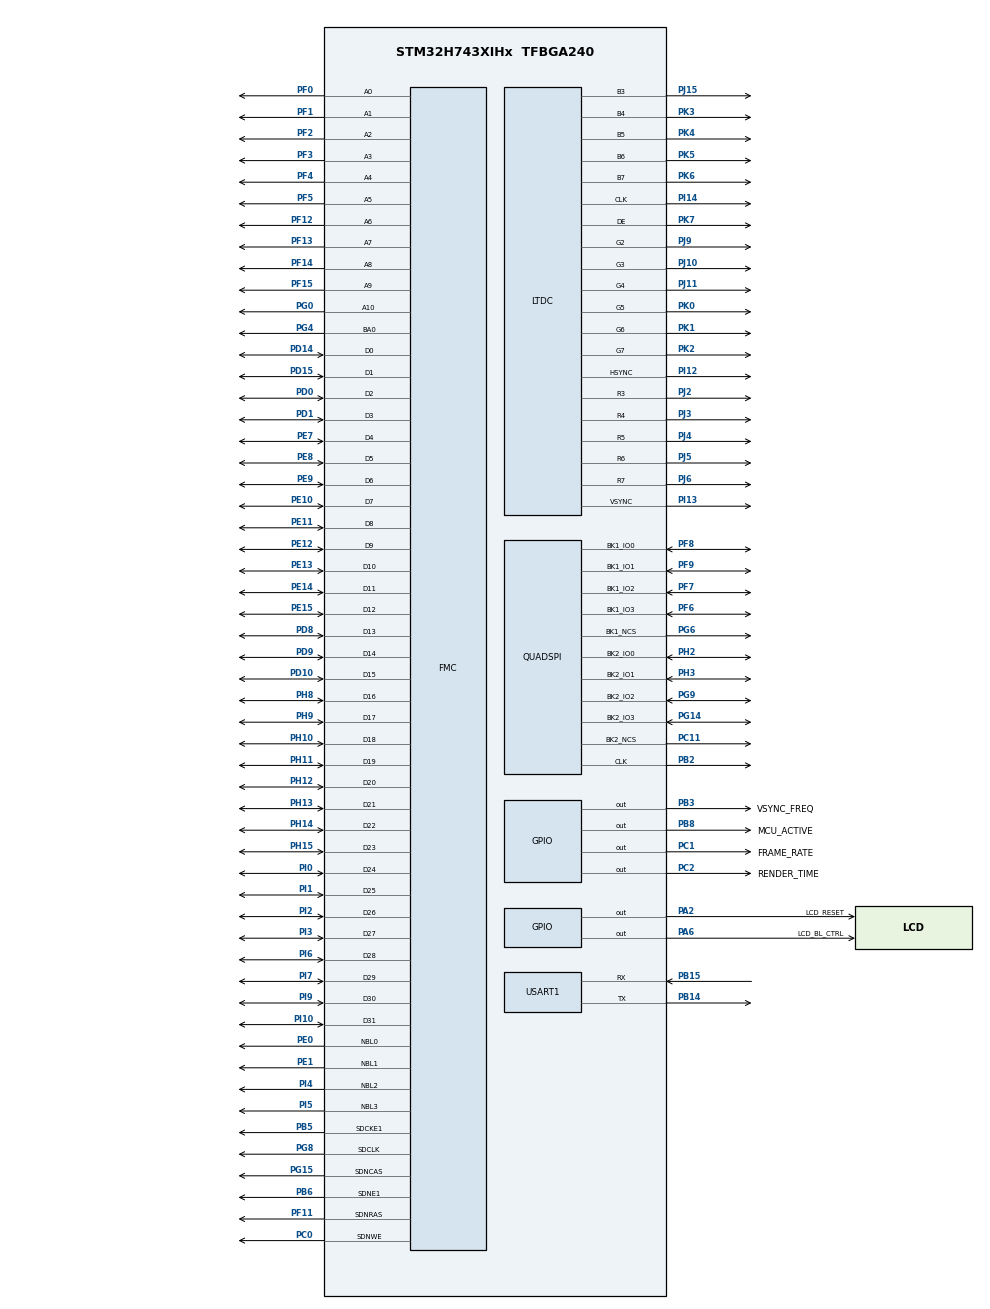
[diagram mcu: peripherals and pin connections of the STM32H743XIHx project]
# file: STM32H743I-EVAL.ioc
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CORTEX_M7.AccessPermission-Cortex_Memory_Protection_Unit_Region0_Settings=MPU_REGION_FULL_ACCESS
CORTEX_M7.AccessPermission-Cortex_Memory_Protection_Unit_Region2_Settings=MPU_REGION_FULL_ACCESS
CORTEX_M7.AccessPermission-Cortex_Memory_Protection_Unit_Region4_Settings=MPU_REGION_FULL_ACCESS
CORTEX_M7.BaseAddress-Cortex_Memory_Protection_Unit_Region0_Settings=0x24000000
CORTEX_M7.BaseAddress-Cortex_Memory_Protection_Unit_Region1_Settings=0xD0000000
CORTEX_M7.BaseAddress-Cortex_Memory_Protection_Unit_Region2_Settings=0xD0000000
CORTEX_M7.BaseAddress-Cortex_Memory_Protection_Unit_Region3_Settings=0x90000000
CORTEX_M7.BaseAddress-Cortex_Memory_Protection_Unit_Region4_Settings=0x90000000
CORTEX_M7.CPU_DCache=Enabled
CORTEX_M7.CPU_ICache=Enabled
CORTEX_M7.DisableExec-Cortex_Memory_Protection_Unit_Region0_Settings=MPU_INSTRUCTION_ACCESS_DISABLE
CORTEX_M7.DisableExec-Cortex_Memory_Protection_Unit_Region1_Settings=MPU_INSTRUCTION_ACCESS_DISABLE
CORTEX_M7.DisableExec-Cortex_Memory_Protection_Unit_Region2_Settings=MPU_INSTRUCTION_ACCESS_DISABLE
CORTEX_M7.DisableExec-Cortex_Memory_Protection_Unit_Region3_Settings=MPU_INSTRUCTION_ACCESS_DISABLE
CORTEX_M7.DisableExec-Cortex_Memory_Protection_Unit_Region4_Settings=MPU_INSTRUCTION_ACCESS_DISABLE
CORTEX_M7.Enable-Cortex_Memory_Protection_Unit_Region0_Settings=MPU_REGION_ENABLE
CORTEX_M7.Enable-Cortex_Memory_Protection_Unit_Region1_Settings=MPU_REGION_ENABLE
CORTEX_M7.Enable-Cortex_Memory_Protection_Unit_Region2_Settings=MPU_REGION_ENABLE
CORTEX_M7.Enable-Cortex_Memory_Protection_Unit_Region3_Settings=MPU_REGION_ENABLE
CORTEX_M7.Enable-Cortex_Memory_Protection_Unit_Region4_Settings=MPU_REGION_ENABLE
CORTEX_M7.IsBufferable-Cortex_Memory_Protection_Unit_Region0_Settings=MPU_ACCESS_BUFFERABLE
CORTEX_M7.IsBufferable-Cortex_Memory_Protection_Unit_Region2_Settings=MPU_ACCESS_BUFFERABLE
CORTEX_M7.IsBufferable-Cortex_Memory_Protection_Unit_Region4_Settings=MPU_ACCESS_NOT_BUFFERABLE
CORTEX_M7.IsCacheable-Cortex_Memory_Protection_Unit_Region0_Settings=MPU_ACCESS_CACHEABLE
CORTEX_M7.IsCacheable-Cortex_Memory_Protection_Unit_Region2_Settings=MPU_ACCESS_CACHEABLE
CORTEX_M7.IsCacheable-Cortex_Memory_Protection_Unit_Region4_Settings=MPU_ACCESS_CACHEABLE
CORTEX_M7.MPU_Control=MPU_PRIVILEGED_DEFAULT
CORTEX_M7.Size-Cortex_Memory_Protection_Unit_Region0_Settings=MPU_REGION_SIZE_512KB
CORTEX_M7.Size-Cortex_Memory_Protection_Unit_Region1_Settings=MPU_REGION_SIZE_512MB
CORTEX_M7.Size-Cortex_Memory_Protection_Unit_Region2_Settings=MPU_REGION_SIZE_32MB
CORTEX_M7.Size-Cortex_Memory_Protection_Unit_Region3_Settings=MPU_REGION_SIZE_512MB
CORTEX_M7.Size-Cortex_Memory_Protection_Unit_Region4_Settings=MPU_REGION_SIZE_128MB
DMA2D.ColorMode=DMA2D_OUTPUT_RGB565
DMA2D.Mode=DMA2D_R2M
FREERTOS.Tasks01=defaultTask,24,128,StartDefaultTask,Default,NULL,Dynamic,NULL,NULL;TouchGFXTask,24,4096,TouchGFX_Task,As external,NULL,Dynamic,NULL,NULL
FREERTOS.configTOTAL_HEAP_SIZE=32768
FREERTOS.configUSE_APPLICATION_TASK_TAG=1
FREERTOS.configUSE_IDLE_HOOK=1
FREERTOS.configUSE_NEWLIB_REENTRANT=1
LTDC.Alpha0_L0=0
LTDC.Alpha_L0=255
LTDC.BlendingFactor1_L0=LTDC_BLENDING_FACTOR1_CA
LTDC.BlendingFactor2_L0=LTDC_BLENDING_FACTOR2_CA
LTDC.FBStartAdress_L0=0xD0000000
LTDC.HBP=114
LTDC.HFP=16
LTDC.HSync=30
LTDC.ImageHeight_L0=480
LTDC.ImageWidth_L0=640
LTDC.Layers=0
LTDC.PixelFormat_L0=LTDC_PIXEL_FORMAT_RGB565
LTDC.VBP=32
LTDC.VFP=10
LTDC.VSync=3
LTDC.WindowX1_L0=640
LTDC.WindowY1_L0=480
Mcu.Family=STM32H7
Mcu.Name=STM32H743XIHx
Mcu.Package=TFBGA240
NVIC.DMA2D_IRQn=true\:5\:0\:false\:false\:true\:true\:true\:true\:true
NVIC.LTDC_IRQn=true\:15\:0\:true\:false\:true\:false\:true\:true\:true
NVIC.PriorityGroup=NVIC_PRIORITYGROUP_4
NVIC.TIM6_DAC_IRQn=true\:0\:0\:false\:false\:true\:false\:false\:true\:true
NVIC.TimeBase=TIM6_DAC_IRQn
NVIC.TimeBaseIP=TIM6
NVIC.USART1_IRQn=true\:5\:0\:false\:false\:true\:true\:true\:true\:true
PA2.GPIO_Label=LCD_RESET
PA2.Signal=GPIO_Output
PA6.GPIO_Label=LCD_BL_CTRL
PA6.GPIO_Speed=GPIO_SPEED_FREQ_HIGH
PA6.PinState=GPIO_PIN_SET
PA6.Signal=GPIO_Output
PB14.Mode=Asynchronous
PB14.Signal=USART1_TX
PB15.Mode=Asynchronous
PB15.Signal=USART1_RX
PB2.GPIO_Speed=GPIO_SPEED_FREQ_VERY_HIGH
PB2.Mode=Dual_Bank
PB2.Signal=QUADSPI_CLK
PB3\ (JTDO/TRACESWO).GPIO_Label=VSYNC_FREQ
PB3\ (JTDO/TRACESWO).GPIO_Speed=GPIO_SPEED_FREQ_VERY_HIGH
PB3\ (JTDO/TRACESWO).Signal=GPIO_Output
PB5.Mode=SdramChipSelect2_1
PB5.Signal=FMC_SDCKE1
PB6.Mode=SdramChipSelect2_1
PB6.Signal=FMC_SDNE1
PB8.GPIO_Label=MCU_ACTIVE
PB8.GPIO_Speed=GPIO_SPEED_FREQ_VERY_HIGH
PB8.Signal=GPIO_Output
PC0.Signal=FMC_SDNWE
PC1.GPIO_Label=FRAME_RATE
PC1.GPIO_Speed=GPIO_SPEED_FREQ_VERY_HIGH
PC1.Signal=GPIO_Output
PC11.GPIO_PuPd=GPIO_PULLUP
PC11.GPIO_Speed=GPIO_SPEED_FREQ_VERY_HIGH
PC11.Mode=Enable Chip Select for each bank
PC11.Signal=QUADSPI_BK2_NCS
PC2.GPIO_Label=RENDER_TIME
PC2.GPIO_Speed=GPIO_SPEED_FREQ_VERY_HIGH
PC2.Signal=GPIO_Output
PD0.Signal=FMC_D2_DA2
PD1.Signal=FMC_D3_DA3
PD10.Signal=FMC_D15_DA15
PD14.Signal=FMC_D0_DA0
PD15.Signal=FMC_D1_DA1
PD8.Signal=FMC_D13_DA13
PD9.Signal=FMC_D14_DA14
PE0.Signal=FMC_NBL0
PE1.Signal=FMC_NBL1
PE10.Signal=FMC_D7_DA7
PE11.Signal=FMC_D8_DA8
PE12.Signal=FMC_D9_DA9
PE13.Signal=FMC_D10_DA10
PE14.Signal=FMC_D11_DA11
PE15.Signal=FMC_D12_DA12
PE7.Signal=FMC_D4_DA4
PE8.Signal=FMC_D5_DA5
PE9.Signal=FMC_D6_DA6
PF0.Signal=FMC_A0
PF1.Signal=FMC_A1
PF11.Signal=FMC_SDNRAS
PF12.Signal=FMC_A6
PF13.Signal=FMC_A7
PF14.Signal=FMC_A8
PF15.Signal=FMC_A9
PF2.Signal=FMC_A2
PF3.Signal=FMC_A3
PF4.Signal=FMC_A4
PF5.Signal=FMC_A5
PF6.GPIO_Speed=GPIO_SPEED_FREQ_VERY_HIGH
PF6.Mode=Dual_Bank
PF6.Signal=QUADSPI_BK1_IO3
PF7.GPIO_Speed=GPIO_SPEED_FREQ_VERY_HIGH
PF7.Mode=Dual_Bank
PF7.Signal=QUADSPI_BK1_IO2
PF8.GPIO_Speed=GPIO_SPEED_FREQ_VERY_HIGH
PF8.Mode=Dual_Bank
PF8.Signal=QUADSPI_BK1_IO0
PF9.GPIO_Speed=GPIO_SPEED_FREQ_VERY_HIGH
PF9.Mode=Dual_Bank
PF9.Signal=QUADSPI_BK1_IO1
PG0.Signal=FMC_A10
PG14.GPIO_Speed=GPIO_SPEED_FREQ_VERY_HIGH
PG14.Mode=Dual_Bank
PG14.Signal=QUADSPI_BK2_IO3
PG15.Signal=FMC_SDNCAS
PG4.Signal=FMC_A14_BA0
PG6.GPIO_PuPd=GPIO_PULLUP
PG6.GPIO_Speed=GPIO_SPEED_FREQ_VERY_HIGH
PG6.Mode=Enable Chip Select for each bank
PG6.Signal=QUADSPI_BK1_NCS
PG8.Signal=FMC_SDCLK
PG9.GPIO_Speed=GPIO_SPEED_FREQ_VERY_HIGH
PG9.Mode=Dual_Bank
PG9.Signal=QUADSPI_BK2_IO2
PH0-OSC_IN\ (PH0).Mode=HSE-External-Oscillator
PH0-OSC_IN\ (PH0).Signal=RCC_OSC_IN
PH1-OSC_OUT\ (PH1).Mode=HSE-External-Oscillator
PH1-OSC_OUT\ (PH1).Signal=RCC_OSC_OUT
PH10.Signal=FMC_D18
PH11.Signal=FMC_D19
PH12.Signal=FMC_D20
PH13.Signal=FMC_D21
PH14.Signal=FMC_D22
PH15.Signal=FMC_D23
PH2.GPIO_Speed=GPIO_SPEED_FREQ_VERY_HIGH
PH2.Mode=Dual_Bank
PH2.Signal=QUADSPI_BK2_IO0
PH3.GPIO_Speed=GPIO_SPEED_FREQ_VERY_HIGH
PH3.Mode=Dual_Bank
PH3.Signal=QUADSPI_BK2_IO1
PH8.Signal=FMC_D16
PH9.Signal=FMC_D17
PI0.Signal=FMC_D24
PI1.Signal=FMC_D25
PI10.Signal=FMC_D31
PI12.GPIO_Speed=GPIO_SPEED_FREQ_VERY_HIGH
PI12.Mode=RGB565
PI12.Signal=LTDC_HSYNC
PI13.GPIO_Speed=GPIO_SPEED_FREQ_VERY_HIGH
PI13.Mode=RGB565
PI13.Signal=LTDC_VSYNC
PI14.GPIO_Speed=GPIO_SPEED_FREQ_VERY_HIGH
PI14.Mode=RGB565
PI14.Signal=LTDC_CLK
PI15.GPIO_Speed=GPIO_SPEED_FREQ_VERY_HIGH
PI15.Signal=LTDC_R0
PI2.Signal=FMC_D26
PI3.Signal=FMC_D27
PI4.Signal=FMC_NBL2
PI5.Signal=FMC_NBL3
PI6.Signal=FMC_D28
PI7.Signal=FMC_D29
PI9.Signal=FMC_D30
PJ0.GPIO_Speed=GPIO_SPEED_FREQ_VERY_HIGH
PJ0.Signal=LTDC_R1
PJ10.GPIO_Speed=GPIO_SPEED_FREQ_VERY_HIGH
PJ10.Mode=RGB565
PJ10.Signal=LTDC_G3
PJ11.GPIO_Speed=GPIO_SPEED_FREQ_VERY_HIGH
PJ11.Mode=RGB565
PJ11.Signal=LTDC_G4
PJ15.GPIO_Speed=GPIO_SPEED_FREQ_VERY_HIGH
PJ15.Mode=RGB565
PJ15.Signal=LTDC_B3
PJ2.GPIO_Speed=GPIO_SPEED_FREQ_VERY_HIGH
PJ2.Mode=RGB565
PJ2.Signal=LTDC_R3
PJ3.GPIO_Speed=GPIO_SPEED_FREQ_VERY_HIGH
PJ3.Mode=RGB565
PJ3.Signal=LTDC_R4
PJ4.GPIO_Speed=GPIO_SPEED_FREQ_VERY_HIGH
PJ4.Mode=RGB565
PJ4.Signal=LTDC_R5
PJ5.GPIO_Speed=GPIO_SPEED_FREQ_VERY_HIGH
PJ5.Mode=RGB565
PJ5.Signal=LTDC_R6
PJ6.GPIO_Speed=GPIO_SPEED_FREQ_VERY_HIGH
PJ6.Mode=RGB565
PJ6.Signal=LTDC_R7
PJ9.GPIO_Speed=GPIO_SPEED_FREQ_VERY_HIGH
PJ9.Mode=RGB565
PJ9.Signal=LTDC_G2
PK0.GPIO_Speed=GPIO_SPEED_FREQ_VERY_HIGH
PK0.Mode=RGB565
PK0.Signal=LTDC_G5
PK1.GPIO_Speed=GPIO_SPEED_FREQ_VERY_HIGH
PK1.Mode=RGB565
PK1.Signal=LTDC_G6
PK2.GPIO_Speed=GPIO_SPEED_FREQ_VERY_HIGH
PK2.Mode=RGB565
PK2.Signal=LTDC_G7
PK3.GPIO_Speed=GPIO_SPEED_FREQ_VERY_HIGH
PK3.Mode=RGB565
PK3.Signal=LTDC_B4
PK4.GPIO_Speed=GPIO_SPEED_FREQ_VERY_HIGH
PK4.Mode=RGB565
PK4.Signal=LTDC_B5
PK5.GPIO_Speed=GPIO_SPEED_FREQ_VERY_HIGH
PK5.Mode=RGB565
PK5.Signal=LTDC_B6
PK6.GPIO_Speed=GPIO_SPEED_FREQ_VERY_HIGH
PK6.Mode=RGB565
PK6.Signal=LTDC_B7
PK7.GPIO_Speed=GPIO_SPEED_FREQ_VERY_HIGH
PK7.Mode=RGB565
PK7.Signal=LTDC_DE
ProjectManager.HeapSize=0x1000
ProjectManager.StackSize=0x1000
ProjectManager.TargetToolchain=STM32CubeIDE
QUADSPI.ChipSelectHighTime=QSPI_CS_HIGH_TIME_4_CYCLE
QUADSPI.ClockPrescaler=3
QUADSPI.FlashSize=26
QUADSPI.SampleShifting=QSPI_SAMPLE_SHIFTING_NONE
RCC.ADCFreq_Value=50390625
RCC.APB1Freq_Value=100000000
RCC.APB2Freq_Value=100000000
RCC.APB3Freq_Value=100000000
RCC.APB4Freq_Value=100000000
RCC.CortexFreq_Value=400000000
RCC.D1PPRE=RCC_APB3_DIV2
RCC.D2PPRE1=RCC_APB1_DIV2
RCC.D2PPRE2=RCC_APB2_DIV2
RCC.D3PPRE=RCC_APB4_DIV2
RCC.DIVM1=5
RCC.DIVM3=5
RCC.DIVN1=160
RCC.DIVN3=160
RCC.DIVQ1=4
RCC.DIVR3=32
RCC.HCLKFreq_Value=200000000
RCC.HPRE=RCC_HCLK_DIV2
RCC.HSE_VALUE=25000000
RCC.PLLFRACN=0
RCC.PLLSourceVirtual=RCC_PLLSOURCE_HSE
RCC.SYSCLKFreq_VALUE=400000000
RCC.SYSCLKSource=RCC_SYSCLKSOURCE_PLLCLK
RCC.USBFreq_Value=200000000
SH.FMC_A0.0=FMC_A0,11b-sda1
SH.FMC_A1.0=FMC_A1,11b-sda1
SH.FMC_A10.0=FMC_A10,11b-sda1
SH.FMC_A14_BA0.0=FMC_BA0,TwoSdramBanks1
SH.FMC_A2.0=FMC_A2,11b-sda1
SH.FMC_A3.0=FMC_A3,11b-sda1
SH.FMC_A4.0=FMC_A4,11b-sda1
SH.FMC_A5.0=FMC_A5,11b-sda1
SH.FMC_A6.0=FMC_A6,11b-sda1
SH.FMC_A7.0=FMC_A7,11b-sda1
SH.FMC_A8.0=FMC_A8,11b-sda1
SH.FMC_A9.0=FMC_A9,11b-sda1
SH.FMC_D0_DA0.0=FMC_D0,sd-32b-d1
SH.FMC_D10_DA10.0=FMC_D10,sd-32b-d1
SH.FMC_D11_DA11.0=FMC_D11,sd-32b-d1
SH.FMC_D12_DA12.0=FMC_D12,sd-32b-d1
SH.FMC_D13_DA13.0=FMC_D13,sd-32b-d1
SH.FMC_D14_DA14.0=FMC_D14,sd-32b-d1
SH.FMC_D15_DA15.0=FMC_D15,sd-32b-d1
SH.FMC_D16.0=FMC_D16,sd-32b-d1
SH.FMC_D17.0=FMC_D17,sd-32b-d1
SH.FMC_D18.0=FMC_D18,sd-32b-d1
SH.FMC_D19.0=FMC_D19,sd-32b-d1
SH.FMC_D1_DA1.0=FMC_D1,sd-32b-d1
SH.FMC_D20.0=FMC_D20,sd-32b-d1
SH.FMC_D21.0=FMC_D21,sd-32b-d1
SH.FMC_D22.0=FMC_D22,sd-32b-d1
SH.FMC_D23.0=FMC_D23,sd-32b-d1
SH.FMC_D24.0=FMC_D24,sd-32b-d1
SH.FMC_D25.0=FMC_D25,sd-32b-d1
SH.FMC_D26.0=FMC_D26,sd-32b-d1
SH.FMC_D27.0=FMC_D27,sd-32b-d1
SH.FMC_D28.0=FMC_D28,sd-32b-d1
SH.FMC_D29.0=FMC_D29,sd-32b-d1
SH.FMC_D2_DA2.0=FMC_D2,sd-32b-d1
SH.FMC_D30.0=FMC_D30,sd-32b-d1
SH.FMC_D31.0=FMC_D31,sd-32b-d1
SH.FMC_D3_DA3.0=FMC_D3,sd-32b-d1
SH.FMC_D4_DA4.0=FMC_D4,sd-32b-d1
SH.FMC_D5_DA5.0=FMC_D5,sd-32b-d1
SH.FMC_D6_DA6.0=FMC_D6,sd-32b-d1
SH.FMC_D7_DA7.0=FMC_D7,sd-32b-d1
SH.FMC_D8_DA8.0=FMC_D8,sd-32b-d1
SH.FMC_D9_DA9.0=FMC_D9,sd-32b-d1
SH.FMC_NBL0.0=FMC_NBL0,Sd4ByteEnable1
SH.FMC_NBL1.0=FMC_NBL1,Sd4ByteEnable1
SH.FMC_NBL2.0=FMC_NBL2,Sd4ByteEnable1
SH.FMC_NBL3.0=FMC_NBL3,Sd4ByteEnable1
SH.FMC_SDCLK.0=FMC_SDCLK,11b-sda1
SH.FMC_SDNCAS.0=FMC_SDNCAS,11b-sda1
SH.FMC_SDNRAS.0=FMC_SDNRAS,11b-sda1
SH.FMC_SDNWE.0=FMC_SDNWE,11b-sda1
STMicroelectronics.X-CUBE-TOUCHGFX.4.22.1.ApplicationCcGraphicsJjApplication=TouchGFXOoGenerator
STMicroelectronics.X-CUBE-TOUCHGFX.4.22.1.tgfx_address1=0xD0000000
STMicroelectronics.X-CUBE-TOUCHGFX.4.22.1.tgfx_address2=0xD0096000
STMicroelectronics.X-CUBE-TOUCHGFX.4.22.1.tgfx_buffering_strategy=Double
STMicroelectronics.X-CUBE-TOUCHGFX.4.22.1.tgfx_display_interface=disp_ltdc
STMicroelectronics.X-CUBE-TOUCHGFX.4.22.1.tgfx_hardware_accelerator=dma_2d
STMicroelectronics.X-CUBE-TOUCHGFX.4.22.1.tgfx_location=By Address
STMicroelectronics.X-CUBE-TOUCHGFX.4.22.1.tgfx_vector_rendering=Enabled
STMicroelectronics.X-CUBE-TOUCHGFX.4.22.1.tgfx_vsync=vsync_ltdc
USART1.VirtualMode-Asynchronous=VM_ASYNC
VP_CRC_VS_CRC.Mode=CRC_Activate
VP_DMA2D_VS_DMA2D.Mode=DMA2D_Activate
VP_FREERTOS_VS_CMSIS_V2.Mode=CMSIS_V2
VP_STMicroelectronics.X-CUBE-TOUCHGFX_VS_GraphicsJjApplication_4.22.1.Mode=GraphicsJjApplication
VP_SYS_VS_tim6.Mode=TIM6
VP_TIM7_VS_ClockSourceINT.Mode=Enable_Timer
board=custom

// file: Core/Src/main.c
/* USER CODE BEGIN Header */
/**
  ******************************************************************************
  * @file           : main.c
  * @brief          : Main program body
  ******************************************************************************
  * @attention
  *
  * <h2><center>&copy; Copyright (c) 2020 STMicroelectronics.
  * All rights reserved.</center></h2>
  *
  * This software component is licensed by ST under Ultimate Liberty license
  * SLA0044, the "License"; You may not use this file except in compliance with
  * the License. You may obtain a copy of the License at:
  *                             www.st.com/SLA0044
  *
  ******************************************************************************
  */
/* USER CODE END Header */
#include "main.h"
#include "cmsis_os.h"
#include "app_touchgfx.h"

/* USER CODE BEGIN Includes */
#include "stm32h743i_eval_sdram.h"
#include "stm32h743i_eval_qspi.h"

/* USER CODE END Includes */

/* USER CODE BEGIN PM */
extern QSPI_HandleTypeDef hqspi __attribute__((weak));
/* USER CODE END PM */

CRC_HandleTypeDef hcrc;

DMA2D_HandleTypeDef hdma2d;

LTDC_HandleTypeDef hltdc;

QSPI_HandleTypeDef hqspi;

TIM_HandleTypeDef htim7;

UART_HandleTypeDef huart1;

SDRAM_HandleTypeDef hsdram1;

uint8_t rx_data;
char recu=0;
char upd_screen=0;
int playerID;

/* Definitions for defaultTask */
osThreadId_t defaultTaskHandle;
const osThreadAttr_t defaultTask_attributes = {
  .name = "defaultTask",
  .stack_size = 128 * 4,
  .priority = (osPriority_t) osPriorityNormal,
};
/* Definitions for TouchGFXTask */
osThreadId_t TouchGFXTaskHandle;
const osThreadAttr_t TouchGFXTask_attributes = {
  .name = "TouchGFXTask",
  .stack_size = 4096 * 4,
  .priority = (osPriority_t) osPriorityNormal,
};

void SystemClock_Config(void);
static void MPU_Config(void);
static void MX_GPIO_Init(void);
static void MX_CRC_Init(void);
static void MX_LTDC_Init(void);
static void MX_FMC_Init(void);
static void MX_DMA2D_Init(void);
static void MX_QUADSPI_Init(void);
static void MX_TIM7_Init(void);
static void MX_USART1_UART_Init(void);
void StartDefaultTask(void *argument);
extern void TouchGFX_Task(void *argument);

int main(void)
{
  /* USER CODE BEGIN 1 */
  *((uint32_t*)0x51046108) = 1; /* DMA2D issue in cut 1.1 */
  *((uint32_t*)0x51008108) = 1; /* AXI SRAM issue in cut 1.2 */
  /* USER CODE END 1 */

  /* MPU Configuration--------------------------------------------------------*/
  MPU_Config();
/* Enable the CPU Cache */

  /* Enable I-Cache---------------------------------------------------------*/
  SCB_EnableICache();

  /* Enable D-Cache---------------------------------------------------------*/
  SCB_EnableDCache();

  /* MCU Configuration--------------------------------------------------------*/

  /* Reset of all peripherals, Initializes the Flash interface and the Systick. */
  HAL_Init();

  /* Configure the system clock */
  SystemClock_Config();

  /* Initialize all configured peripherals */
  MX_GPIO_Init();
  MX_CRC_Init();
  MX_LTDC_Init();
  MX_FMC_Init();
  MX_DMA2D_Init();
  MX_QUADSPI_Init();
  MX_TIM7_Init();
  MX_USART1_UART_Init();
  __HAL_UART_DISABLE(&huart1);
  MX_TouchGFX_Init();
  /* Call PreOsInit function */
  MX_TouchGFX_PreOSInit();
  /* USER CODE BEGIN 2 */

  HAL_UART_Receive_IT(&huart1,&rx_data,1);

  /* USER CODE END 2 */

  /* Init scheduler */
  osKernelInitialize();

  /* Create the thread(s) */
  /* creation of defaultTask */
  defaultTaskHandle = osThreadNew(StartDefaultTask, NULL, &defaultTask_attributes);

  /* creation of TouchGFXTask */
  TouchGFXTaskHandle = osThreadNew(TouchGFX_Task, NULL, &TouchGFXTask_attributes);

  /* Start scheduler */
  osKernelStart();

  /* We should never get here as control is now taken by the scheduler */
  /* Infinite loop */
  while (1)
  {

  }
}

void SystemClock_Config(void)
{
  RCC_OscInitTypeDef RCC_OscInitStruct = {0};
  RCC_ClkInitTypeDef RCC_ClkInitStruct = {0};

  /** Supply configuration update enable
  */
  HAL_PWREx_ConfigSupply(PWR_LDO_SUPPLY);

  /** Configure the main internal regulator output voltage
  */
  __HAL_PWR_VOLTAGESCALING_CONFIG(PWR_REGULATOR_VOLTAGE_SCALE1);

  while(!__HAL_PWR_GET_FLAG(PWR_FLAG_VOSRDY)) {}

  /** Initializes the RCC Oscillators according to the specified parameters
  * in the RCC_OscInitTypeDef structure.
  */
  RCC_OscInitStruct.OscillatorType = RCC_OSCILLATORTYPE_HSE;
  RCC_OscInitStruct.HSEState = RCC_HSE_ON;
  RCC_OscInitStruct.PLL.PLLState = RCC_PLL_ON;
  RCC_OscInitStruct.PLL.PLLSource = RCC_PLLSOURCE_HSE;
  RCC_OscInitStruct.PLL.PLLM = 5;
  RCC_OscInitStruct.PLL.PLLN = 160;
  RCC_OscInitStruct.PLL.PLLP = 2;
  RCC_OscInitStruct.PLL.PLLQ = 4;
  RCC_OscInitStruct.PLL.PLLR = 2;
  RCC_OscInitStruct.PLL.PLLRGE = RCC_PLL1VCIRANGE_2;
  RCC_OscInitStruct.PLL.PLLVCOSEL = RCC_PLL1VCOWIDE;
  RCC_OscInitStruct.PLL.PLLFRACN = 0;
  if (HAL_RCC_OscConfig(&RCC_OscInitStruct) != HAL_OK)
  {
    Error_Handler();
  }

  /** Initializes the CPU, AHB and APB buses clocks
  */
  RCC_ClkInitStruct.ClockType = RCC_CLOCKTYPE_HCLK|RCC_CLOCKTYPE_SYSCLK
                              |RCC_CLOCKTYPE_PCLK1|RCC_CLOCKTYPE_PCLK2
                              |RCC_CLOCKTYPE_D3PCLK1|RCC_CLOCKTYPE_D1PCLK1;
  RCC_ClkInitStruct.SYSCLKSource = RCC_SYSCLKSOURCE_PLLCLK;
  RCC_ClkInitStruct.SYSCLKDivider = RCC_SYSCLK_DIV1;
  RCC_ClkInitStruct.AHBCLKDivider = RCC_HCLK_DIV2;
  RCC_ClkInitStruct.APB3CLKDivider = RCC_APB3_DIV2;
  RCC_ClkInitStruct.APB1CLKDivider = RCC_APB1_DIV2;
  RCC_ClkInitStruct.APB2CLKDivider = RCC_APB2_DIV2;
  RCC_ClkInitStruct.APB4CLKDivider = RCC_APB4_DIV2;

  if (HAL_RCC_ClockConfig(&RCC_ClkInitStruct, FLASH_LATENCY_2) != HAL_OK)
  {
    Error_Handler();
  }
}

static void MX_CRC_Init(void)
{

  hcrc.Instance = CRC;
  hcrc.Init.DefaultPolynomialUse = DEFAULT_POLYNOMIAL_ENABLE;
  hcrc.Init.DefaultInitValueUse = DEFAULT_INIT_VALUE_ENABLE;
  hcrc.Init.InputDataInversionMode = CRC_INPUTDATA_INVERSION_NONE;
  hcrc.Init.OutputDataInversionMode = CRC_OUTPUTDATA_INVERSION_DISABLE;
  hcrc.InputDataFormat = CRC_INPUTDATA_FORMAT_BYTES;
  if (HAL_CRC_Init(&hcrc) != HAL_OK)
  {
    Error_Handler();
  }

}

static void MX_DMA2D_Init(void)
{

  hdma2d.Instance = DMA2D;
  hdma2d.Init.Mode = DMA2D_R2M;
  hdma2d.Init.ColorMode = DMA2D_OUTPUT_RGB565;
  hdma2d.Init.OutputOffset = 0;
  if (HAL_DMA2D_Init(&hdma2d) != HAL_OK)
  {
    Error_Handler();
  }

}

static void MX_LTDC_Init(void)
{

  LTDC_LayerCfgTypeDef pLayerCfg = {0};

  hltdc.Instance = LTDC;
  hltdc.Init.HSPolarity = LTDC_HSPOLARITY_AL;
  hltdc.Init.VSPolarity = LTDC_VSPOLARITY_AL;
  hltdc.Init.DEPolarity = LTDC_DEPOLARITY_AL;
  hltdc.Init.PCPolarity = LTDC_PCPOLARITY_IPC;
  hltdc.Init.HorizontalSync = 29;
  hltdc.Init.VerticalSync = 2;
  hltdc.Init.AccumulatedHBP = 143;
  hltdc.Init.AccumulatedVBP = 34;
  hltdc.Init.AccumulatedActiveW = 783;
  hltdc.Init.AccumulatedActiveH = 514;
  hltdc.Init.TotalWidth = 799;
  hltdc.Init.TotalHeigh = 524;
  hltdc.Init.Backcolor.Blue = 0;
  hltdc.Init.Backcolor.Green = 0;
  hltdc.Init.Backcolor.Red = 0;
  if (HAL_LTDC_Init(&hltdc) != HAL_OK)
  {
    Error_Handler();
  }
  pLayerCfg.WindowX0 = 0;
  pLayerCfg.WindowX1 = 640;
  pLayerCfg.WindowY0 = 0;
  pLayerCfg.WindowY1 = 480;
  pLayerCfg.PixelFormat = LTDC_PIXEL_FORMAT_RGB565;
  pLayerCfg.Alpha = 255;
  pLayerCfg.Alpha0 = 0;
  pLayerCfg.BlendingFactor1 = LTDC_BLENDING_FACTOR1_CA;
  pLayerCfg.BlendingFactor2 = LTDC_BLENDING_FACTOR2_CA;
  pLayerCfg.FBStartAdress = 0xD0000000;
  pLayerCfg.ImageWidth = 640;
  pLayerCfg.ImageHeight = 480;
  pLayerCfg.Backcolor.Blue = 0;
  pLayerCfg.Backcolor.Green = 0;
  pLayerCfg.Backcolor.Red = 0;
  if (HAL_LTDC_ConfigLayer(&hltdc, &pLayerCfg, 0) != HAL_OK)
  {
    Error_Handler();
  }
  /* USER CODE BEGIN LTDC_Init 2 */
  // HAL_LTDC_EnableDither(&hltdc);
  /* USER CODE END LTDC_Init 2 */

}

static void MX_QUADSPI_Init(void)
{

  /* QUADSPI parameter configuration*/
  hqspi.Instance = QUADSPI;
  hqspi.Init.ClockPrescaler = 3;
  hqspi.Init.FifoThreshold = 1;
  hqspi.Init.SampleShifting = QSPI_SAMPLE_SHIFTING_NONE;
  hqspi.Init.FlashSize = 26;
  hqspi.Init.ChipSelectHighTime = QSPI_CS_HIGH_TIME_4_CYCLE;
  hqspi.Init.ClockMode = QSPI_CLOCK_MODE_0;
  hqspi.Init.DualFlash = QSPI_DUALFLASH_ENABLE;
  if (HAL_QSPI_Init(&hqspi) != HAL_OK)
  {
    Error_Handler();
  }
  /* USER CODE BEGIN QUADSPI_Init 2 */
  BSP_QSPI_DeInit (0);

  BSP_QSPI_Init_t init ;
  init.InterfaceMode  = MT25TL01G_QPI_MODE;
  init.TransferRate   = MT25TL01G_DTR_TRANSFER;
  init.DualFlashMode  = MT25TL01G_DUALFLASH_ENABLE;

  if(BSP_QSPI_Init(0,&init) != BSP_ERROR_NONE)
  {
    Error_Handler();
  }
  if(BSP_QSPI_EnableMemoryMappedMode(0) != BSP_ERROR_NONE)
  {
    Error_Handler();
  }
  HAL_NVIC_DisableIRQ(QUADSPI_IRQn);
  /* USER CODE END QUADSPI_Init 2 */

}

static void MX_TIM7_Init(void)
{

  TIM_MasterConfigTypeDef sMasterConfig = {0};

  htim7.Instance = TIM7;
  htim7.Init.Prescaler = 0;
  htim7.Init.CounterMode = TIM_COUNTERMODE_UP;
  htim7.Init.Period = 65535;
  htim7.Init.AutoReloadPreload = TIM_AUTORELOAD_PRELOAD_DISABLE;
  if (HAL_TIM_Base_Init(&htim7) != HAL_OK)
  {
    Error_Handler();
  }
  sMasterConfig.MasterOutputTrigger = TIM_TRGO_RESET;
  sMasterConfig.MasterSlaveMode = TIM_MASTERSLAVEMODE_DISABLE;
  if (HAL_TIMEx_MasterConfigSynchronization(&htim7, &sMasterConfig) != HAL_OK)
  {
    Error_Handler();
  }

}

static void MX_USART1_UART_Init(void)
{

  huart1.Instance = USART1;
  huart1.Init.BaudRate = 115200;
  huart1.Init.WordLength = UART_WORDLENGTH_8B;
  huart1.Init.StopBits = UART_STOPBITS_1;
  huart1.Init.Parity = UART_PARITY_NONE;
  huart1.Init.Mode = UART_MODE_TX_RX;
  huart1.Init.HwFlowCtl = UART_HWCONTROL_NONE;
  huart1.Init.OverSampling = UART_OVERSAMPLING_16;
  huart1.Init.OneBitSampling = UART_ONE_BIT_SAMPLE_DISABLE;
  huart1.Init.ClockPrescaler = UART_PRESCALER_DIV1;
  huart1.AdvancedInit.AdvFeatureInit = UART_ADVFEATURE_NO_INIT;
  if (HAL_UART_Init(&huart1) != HAL_OK)
  {
    Error_Handler();
  }
  if (HAL_UARTEx_SetTxFifoThreshold(&huart1, UART_TXFIFO_THRESHOLD_1_8) != HAL_OK)
  {
    Error_Handler();
  }
  if (HAL_UARTEx_SetRxFifoThreshold(&huart1, UART_RXFIFO_THRESHOLD_1_8) != HAL_OK)
  {
    Error_Handler();
  }
  if (HAL_UARTEx_DisableFifoMode(&huart1) != HAL_OK)
  {
    Error_Handler();
  }

}

void SendByte_Uart1(uint8_t data)
{
	USART1->TDR = data;
	while((USART1->ISR & 0x00000020));		/*check for transmission complete*/
}

void HAL_UART_RxCpltCallback(UART_HandleTypeDef *huart)
{
	recu=1;
	HAL_UART_Receive_IT(&huart1,&rx_data,1); //start next data receive interrupt
}

/* FMC initialization function */
static void MX_FMC_Init(void)
{

  FMC_SDRAM_TimingTypeDef SdramTiming = {0};

  /** Perform the SDRAM1 memory initialization sequence
  */
  hsdram1.Instance = FMC_SDRAM_DEVICE;
  /* hsdram1.Init */
  hsdram1.Init.SDBank = FMC_SDRAM_BANK2;
  hsdram1.Init.ColumnBitsNumber = FMC_SDRAM_COLUMN_BITS_NUM_8;
  hsdram1.Init.RowBitsNumber = FMC_SDRAM_ROW_BITS_NUM_11;
  hsdram1.Init.MemoryDataWidth = FMC_SDRAM_MEM_BUS_WIDTH_32;
  hsdram1.Init.InternalBankNumber = FMC_SDRAM_INTERN_BANKS_NUM_2;
  hsdram1.Init.CASLatency = FMC_SDRAM_CAS_LATENCY_1;
  hsdram1.Init.WriteProtection = FMC_SDRAM_WRITE_PROTECTION_DISABLE;
  hsdram1.Init.SDClockPeriod = FMC_SDRAM_CLOCK_DISABLE;
  hsdram1.Init.ReadBurst = FMC_SDRAM_RBURST_DISABLE;
  hsdram1.Init.ReadPipeDelay = FMC_SDRAM_RPIPE_DELAY_0;
  /* SdramTiming */
  SdramTiming.LoadToActiveDelay = 16;
  SdramTiming.ExitSelfRefreshDelay = 16;
  SdramTiming.SelfRefreshTime = 16;
  SdramTiming.RowCycleDelay = 16;
  SdramTiming.WriteRecoveryTime = 16;
  SdramTiming.RPDelay = 16;
  SdramTiming.RCDDelay = 16;

  if (HAL_SDRAM_Init(&hsdram1, &SdramTiming) != HAL_OK)
  {
    Error_Handler( );
  }

  /* USER CODE BEGIN FMC_Init 2 */
  /* Disable FMC Bank1 to avoid speculative/cache accesses */
  FMC_Bank1_R->BTCR[0] &= ~FMC_BCRx_MBKEN;

  BSP_SDRAM_DeInit(0);
  BSP_SDRAM_Init(0);
  /* USER CODE END FMC_Init 2 */
}

static void MX_GPIO_Init(void)
{
  GPIO_InitTypeDef GPIO_InitStruct = {0};

  /* GPIO Ports Clock Enable */
  __HAL_RCC_GPIOI_CLK_ENABLE();
  __HAL_RCC_GPIOB_CLK_ENABLE();
  __HAL_RCC_GPIOK_CLK_ENABLE();
  __HAL_RCC_GPIOG_CLK_ENABLE();
  __HAL_RCC_GPIOE_CLK_ENABLE();
  __HAL_RCC_GPIOJ_CLK_ENABLE();
  __HAL_RCC_GPIOC_CLK_ENABLE();
  __HAL_RCC_GPIOH_CLK_ENABLE();
  __HAL_RCC_GPIOD_CLK_ENABLE();
  __HAL_RCC_GPIOF_CLK_ENABLE();
  __HAL_RCC_GPIOA_CLK_ENABLE();

  /*Configure GPIO pin Output Level */
  HAL_GPIO_WritePin(GPIOB, VSYNC_FREQ_Pin|MCU_ACTIVE_Pin, GPIO_PIN_RESET);

  /*Configure GPIO pin Output Level */
  HAL_GPIO_WritePin(GPIOC, FRAME_RATE_Pin|RENDER_TIME_Pin, GPIO_PIN_RESET);

  /*Configure GPIO pin Output Level */
  HAL_GPIO_WritePin(LCD_RESET_GPIO_Port, LCD_RESET_Pin, GPIO_PIN_RESET);

  /*Configure GPIO pin Output Level */
  HAL_GPIO_WritePin(LCD_BL_CTRL_GPIO_Port, LCD_BL_CTRL_Pin, GPIO_PIN_SET);

  /*Configure GPIO pins : VSYNC_FREQ_Pin MCU_ACTIVE_Pin */
  GPIO_InitStruct.Pin = VSYNC_FREQ_Pin|MCU_ACTIVE_Pin;
  GPIO_InitStruct.Mode = GPIO_MODE_OUTPUT_PP;
  GPIO_InitStruct.Pull = GPIO_NOPULL;
  GPIO_InitStruct.Speed = GPIO_SPEED_FREQ_VERY_HIGH;
  HAL_GPIO_Init(GPIOB, &GPIO_InitStruct);

  /*Configure GPIO pins : FRAME_RATE_Pin RENDER_TIME_Pin */
  GPIO_InitStruct.Pin = FRAME_RATE_Pin|RENDER_TIME_Pin;
  GPIO_InitStruct.Mode = GPIO_MODE_OUTPUT_PP;
  GPIO_InitStruct.Pull = GPIO_NOPULL;
  GPIO_InitStruct.Speed = GPIO_SPEED_FREQ_VERY_HIGH;
  HAL_GPIO_Init(GPIOC, &GPIO_InitStruct);

  /*Configure GPIO pin : LCD_RESET_Pin */
  GPIO_InitStruct.Pin = LCD_RESET_Pin;
  GPIO_InitStruct.Mode = GPIO_MODE_OUTPUT_PP;
  GPIO_InitStruct.Pull = GPIO_NOPULL;
  GPIO_InitStruct.Speed = GPIO_SPEED_FREQ_LOW;
  HAL_GPIO_Init(LCD_RESET_GPIO_Port, &GPIO_InitStruct);

  /*Configure GPIO pin : LCD_BL_CTRL_Pin */
  GPIO_InitStruct.Pin = LCD_BL_CTRL_Pin;
  GPIO_InitStruct.Mode = GPIO_MODE_OUTPUT_PP;
  GPIO_InitStruct.Pull = GPIO_NOPULL;
  GPIO_InitStruct.Speed = GPIO_SPEED_FREQ_HIGH;
  HAL_GPIO_Init(LCD_BL_CTRL_GPIO_Port, &GPIO_InitStruct);

}

void StartDefaultTask(void *argument)
{
  /* USER CODE BEGIN 5 */
  /* Infinite loop */
  for(;;)
  {
    osDelay(100);
  }
  /* USER CODE END 5 */
}

/* MPU Configuration */

void MPU_Config(void)
{
  MPU_Region_InitTypeDef MPU_InitStruct = {0};

  /* Disables the MPU */
  HAL_MPU_Disable();

  /** Initializes and configures the Region and the memory to be protected
  */
  MPU_InitStruct.Enable = MPU_REGION_ENABLE;
  MPU_InitStruct.Number = MPU_REGION_NUMBER0;
  MPU_InitStruct.BaseAddress = 0x24000000;
  MPU_InitStruct.Size = MPU_REGION_SIZE_512KB;
  MPU_InitStruct.SubRegionDisable = 0x0;
  MPU_InitStruct.TypeExtField = MPU_TEX_LEVEL0;
  MPU_InitStruct.AccessPermission = MPU_REGION_FULL_ACCESS;
  MPU_InitStruct.DisableExec = MPU_INSTRUCTION_ACCESS_DISABLE;
  MPU_InitStruct.IsShareable = MPU_ACCESS_NOT_SHAREABLE;
  MPU_InitStruct.IsCacheable = MPU_ACCESS_CACHEABLE;
  MPU_InitStruct.IsBufferable = MPU_ACCESS_BUFFERABLE;

  HAL_MPU_ConfigRegion(&MPU_InitStruct);

  /** Initializes and configures the Region and the memory to be protected
  */
  MPU_InitStruct.Number = MPU_REGION_NUMBER1;
  MPU_InitStruct.BaseAddress = 0xD0000000;
  MPU_InitStruct.Size = MPU_REGION_SIZE_512MB;
  MPU_InitStruct.AccessPermission = MPU_REGION_NO_ACCESS;
  MPU_InitStruct.IsCacheable = MPU_ACCESS_NOT_CACHEABLE;
  MPU_InitStruct.IsBufferable = MPU_ACCESS_NOT_BUFFERABLE;

  HAL_MPU_ConfigRegion(&MPU_InitStruct);

  /** Initializes and configures the Region and the memory to be protected
  */
  MPU_InitStruct.Number = MPU_REGION_NUMBER2;
  MPU_InitStruct.Size = MPU_REGION_SIZE_32MB;
  MPU_InitStruct.AccessPermission = MPU_REGION_FULL_ACCESS;
  MPU_InitStruct.IsCacheable = MPU_ACCESS_CACHEABLE;
  MPU_InitStruct.IsBufferable = MPU_ACCESS_BUFFERABLE;

  HAL_MPU_ConfigRegion(&MPU_InitStruct);

  /** Initializes and configures the Region and the memory to be protected
  */
  MPU_InitStruct.Number = MPU_REGION_NUMBER3;
  MPU_InitStruct.BaseAddress = 0x90000000;
  MPU_InitStruct.Size = MPU_REGION_SIZE_512MB;
  MPU_InitStruct.AccessPermission = MPU_REGION_NO_ACCESS;
  MPU_InitStruct.IsCacheable = MPU_ACCESS_NOT_CACHEABLE;
  MPU_InitStruct.IsBufferable = MPU_ACCESS_NOT_BUFFERABLE;

  HAL_MPU_ConfigRegion(&MPU_InitStruct);

  /** Initializes and configures the Region and the memory to be protected
  */
  MPU_InitStruct.Number = MPU_REGION_NUMBER4;
  MPU_InitStruct.Size = MPU_REGION_SIZE_128MB;
  MPU_InitStruct.AccessPermission = MPU_REGION_FULL_ACCESS;
  MPU_InitStruct.IsCacheable = MPU_ACCESS_CACHEABLE;

  HAL_MPU_ConfigRegion(&MPU_InitStruct);
  /* Enables the MPU */
  HAL_MPU_Enable(MPU_PRIVILEGED_DEFAULT);

}

void HAL_TIM_PeriodElapsedCallback(TIM_HandleTypeDef *htim)
{
  if (htim->Instance == TIM6) {
    HAL_IncTick();
  }
}

void Error_Handler(void)
{
}

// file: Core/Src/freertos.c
/* USER CODE BEGIN Header */
/**
  ******************************************************************************
  * File Name          : freertos.c
  * Description        : Code for freertos applications
  ******************************************************************************
  * @attention
  *
  * <h2><center>&copy; Copyright (c) 2020 STMicroelectronics.
  * All rights reserved.</center></h2>
  *
  * This software component is licensed by ST under Ultimate Liberty license
  * SLA0044, the "License"; You may not use this file except in compliance with
  * the License. You may obtain a copy of the License at:
  *                             www.st.com/SLA0044
  *
  ******************************************************************************
  */
/* USER CODE END Header */

#include "FreeRTOS.h"
#include "task.h"
#include "main.h"

/* USER CODE BEGIN FunctionPrototypes */
extern portBASE_TYPE IdleTaskHook(void* p);
/* USER CODE END FunctionPrototypes */

/* Hook prototypes */
void vApplicationIdleHook(void);

/* USER CODE BEGIN 2 */
void vApplicationIdleHook( void )
{
   /* vApplicationIdleHook() will only be called if configUSE_IDLE_HOOK is set
   to 1 in FreeRTOSConfig.h. It will be called on each iteration of the idle
   task. It is essential that code added to this hook function never attempts
   to block in any way (for example, call xQueueReceive() with a block time
   specified, or call vTaskDelay()). If the application makes use of the
   vTaskDelete() API function (as this demo application does) then it is also
   important that vApplicationIdleHook() is permitted to return to its calling
   function, because it is the responsibility of the idle task to clean up
   memory allocated by the kernel to any task that has since been deleted. */

  vTaskSetApplicationTaskTag(NULL, IdleTaskHook);
}
/* USER CODE END 2 */
